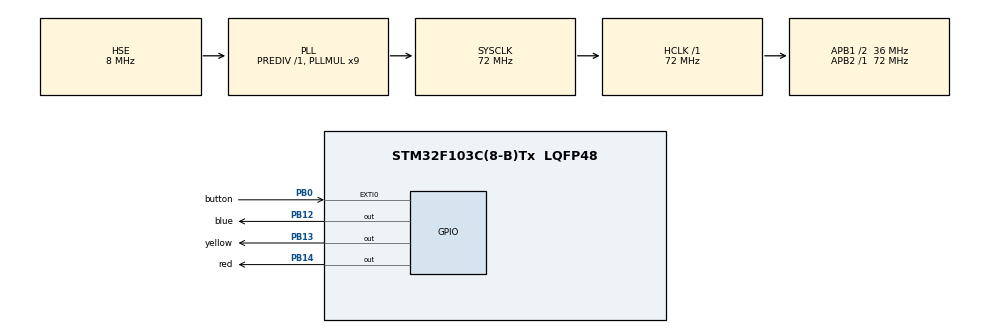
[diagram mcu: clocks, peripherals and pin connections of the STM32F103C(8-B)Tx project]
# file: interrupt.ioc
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Mcu.Family=STM32F1
Mcu.Name=STM32F103C(8-B)Tx
Mcu.Package=LQFP48
NVIC.EXTI0_IRQn=true\:10\:0\:true\:false\:true\:true\:true\:true
NVIC.PriorityGroup=NVIC_PRIORITYGROUP_4
PA13.Mode=Serial_Wire
PA13.Signal=SYS_JTMS-SWDIO
PA14.Mode=Serial_Wire
PA14.Signal=SYS_JTCK-SWCLK
PB0.GPIO_Label=button
PB0.GPIO_ModeDefaultEXTI=GPIO_MODE_IT_RISING
PB0.GPIO_PuPd=GPIO_PULLUP
PB0.Signal=GPXTI0
PB12.GPIO_Label=blue
PB12.GPIO_PuPd=GPIO_PULLDOWN
PB12.Signal=GPIO_Output
PB13.GPIO_Label=yellow
PB13.GPIO_PuPd=GPIO_PULLDOWN
PB13.Signal=GPIO_Output
PB14.GPIO_Label=red
PB14.GPIO_PuPd=GPIO_PULLDOWN
PB14.Signal=GPIO_Output
PD0-OSC_IN.Mode=HSE-External-Oscillator
PD0-OSC_IN.Signal=RCC_OSC_IN
PD1-OSC_OUT.Mode=HSE-External-Oscillator
PD1-OSC_OUT.Signal=RCC_OSC_OUT
ProjectManager.HeapSize=0x200
ProjectManager.StackSize=0x400
ProjectManager.TargetToolchain=STM32CubeIDE
RCC.AHBFreq_Value=72000000
RCC.APB1CLKDivider=RCC_HCLK_DIV2
RCC.APB1Freq_Value=36000000
RCC.APB1TimFreq_Value=72000000
RCC.APB2Freq_Value=72000000
RCC.APB2TimFreq_Value=72000000
RCC.HCLKFreq_Value=72000000
RCC.PLLMUL=RCC_PLL_MUL9
RCC.PLLSourceVirtual=RCC_PLLSOURCE_HSE
RCC.SYSCLKFreq_VALUE=72000000
RCC.SYSCLKSource=RCC_SYSCLKSOURCE_PLLCLK
RCC.USBFreq_Value=72000000
board=custom

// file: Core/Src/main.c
/* USER CODE BEGIN Header */
/**
  ******************************************************************************
  * @file           : main.c
  * @brief          : Main program body
  ******************************************************************************
  * @attention
  *
  * Copyright (c) 2024 STMicroelectronics.
  * All rights reserved.
  *
  * This software is licensed under terms that can be found in the LICENSE file
  * in the root directory of this software component.
  * If no LICENSE file comes with this software, it is provided AS-IS.
  *
  ******************************************************************************
  */
/* USER CODE END Header */
#include "main.h"

/* USER CODE BEGIN Includes */
#include <stdio.h>
/* USER CODE END Includes */

/* USER CODE BEGIN PTD */
//int _write(int file, char *data, int len) {
//    for (int i = 0; i < len; i++) {
//        ITM_SendChar(data[i]);
//    }
//    return len;
//}
/* USER CODE END PTD */

/* USER CODE BEGIN PV */
uint8_t button_flag = 0;
/* USER CODE END PV */

void SystemClock_Config(void);
static void MX_GPIO_Init(void);

/* USER CODE BEGIN 0 */
void HAL_GPIO_EXTI_Callback(uint16_t GPIO_Pin) {
	printf("Chegou aqui.. \n");
	HAL_GPIO_TogglePin(GPIOB, yellow_Pin);
}
/* USER CODE END 0 */

int main(void)
{

  /* MCU Configuration--------------------------------------------------------*/

  /* Reset of all peripherals, Initializes the Flash interface and the Systick. */
  HAL_Init();

  /* Configure the system clock */
  SystemClock_Config();

  /* Initialize all configured peripherals */
  MX_GPIO_Init();

  /* Infinite loop */
  /* USER CODE BEGIN WHILE */
  while (1)
  {
//	  ITM_SendChar('H');  // Envia o caractere 'H' para o SWO
//	  ITM_SendChar('i');
	  printf("TESTE CONSOLE \n");
	  HAL_Delay(500);
    /* USER CODE END WHILE */

  }
}

void SystemClock_Config(void)
{
  RCC_OscInitTypeDef RCC_OscInitStruct = {0};
  RCC_ClkInitTypeDef RCC_ClkInitStruct = {0};

  /** Initializes the RCC Oscillators according to the specified parameters
  * in the RCC_OscInitTypeDef structure.
  */
  RCC_OscInitStruct.OscillatorType = RCC_OSCILLATORTYPE_HSE;
  RCC_OscInitStruct.HSEState = RCC_HSE_ON;
  RCC_OscInitStruct.HSEPredivValue = RCC_HSE_PREDIV_DIV1;
  RCC_OscInitStruct.HSIState = RCC_HSI_ON;
  RCC_OscInitStruct.PLL.PLLState = RCC_PLL_ON;
  RCC_OscInitStruct.PLL.PLLSource = RCC_PLLSOURCE_HSE;
  RCC_OscInitStruct.PLL.PLLMUL = RCC_PLL_MUL9;
  if (HAL_RCC_OscConfig(&RCC_OscInitStruct) != HAL_OK)
  {
    Error_Handler();
  }

  /** Initializes the CPU, AHB and APB buses clocks
  */
  RCC_ClkInitStruct.ClockType = RCC_CLOCKTYPE_HCLK|RCC_CLOCKTYPE_SYSCLK
                              |RCC_CLOCKTYPE_PCLK1|RCC_CLOCKTYPE_PCLK2;
  RCC_ClkInitStruct.SYSCLKSource = RCC_SYSCLKSOURCE_PLLCLK;
  RCC_ClkInitStruct.AHBCLKDivider = RCC_SYSCLK_DIV1;
  RCC_ClkInitStruct.APB1CLKDivider = RCC_HCLK_DIV2;
  RCC_ClkInitStruct.APB2CLKDivider = RCC_HCLK_DIV1;

  if (HAL_RCC_ClockConfig(&RCC_ClkInitStruct, FLASH_LATENCY_2) != HAL_OK)
  {
    Error_Handler();
  }
}

static void MX_GPIO_Init(void)
{
  GPIO_InitTypeDef GPIO_InitStruct = {0};

  /* GPIO Ports Clock Enable */
  __HAL_RCC_GPIOD_CLK_ENABLE();
  __HAL_RCC_GPIOB_CLK_ENABLE();
  __HAL_RCC_GPIOA_CLK_ENABLE();

  /*Configure GPIO pin Output Level */
  HAL_GPIO_WritePin(GPIOB, blue_Pin|yellow_Pin|red_Pin, GPIO_PIN_RESET);

  /*Configure GPIO pin : button_Pin */
  GPIO_InitStruct.Pin = button_Pin;
  GPIO_InitStruct.Mode = GPIO_MODE_IT_RISING;
  GPIO_InitStruct.Pull = GPIO_PULLUP;
  HAL_GPIO_Init(button_GPIO_Port, &GPIO_InitStruct);

  /*Configure GPIO pins : blue_Pin yellow_Pin red_Pin */
  GPIO_InitStruct.Pin = blue_Pin|yellow_Pin|red_Pin;
  GPIO_InitStruct.Mode = GPIO_MODE_OUTPUT_PP;
  GPIO_InitStruct.Pull = GPIO_PULLDOWN;
  GPIO_InitStruct.Speed = GPIO_SPEED_FREQ_LOW;
  HAL_GPIO_Init(GPIOB, &GPIO_InitStruct);

  /* EXTI interrupt init*/
  HAL_NVIC_SetPriority(EXTI0_IRQn, 10, 0);
  HAL_NVIC_EnableIRQ(EXTI0_IRQn);

}

/* USER CODE BEGIN 4 */
int _write(int file, char *ptr, int len)
{
  (void)file;
  int DataIdx;

  for (DataIdx = 0; DataIdx < len; DataIdx++)
  {
    ITM_SendChar(*ptr++);
  }
  return len;
}

/* USER CODE END 4 */

void Error_Handler(void)
{
  __disable_irq();
  while (1)
  {
  }
}
